AUTOSAR XML (schema 00044)
package /ComponentTypes
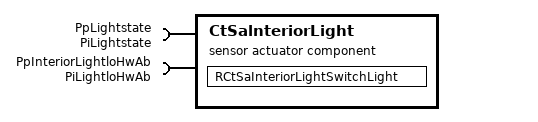
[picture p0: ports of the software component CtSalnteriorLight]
  sensor actuator sw component type CtSalnteriorLight
    require port PpLightstate: nonqueued-receiver-com-spec{data-element=DeLightstate, init-value=constant-reference=Clightoff}, required-interface=PiLightstate
    require port PpInteriorLightloHwAb: client-com-spec=WriteChannel, required-interface=PiLightloHwAb
    behavior CtSalnteriorLight_InternalBehavior: data-type-mapping=DemoTypeMapping, supports-multiple-instantiation=true
      data received event DRT_RCtSaInteriorLightSwitchLight_PpLightstate_DeLightstate: start-on-event=RCtSaInteriorLightSwitchLight, data=PpLightstate.DeLightstate
      runnable RCtSaInteriorLightSwitchLight
        data-receive-point-by-arguments:
          access REC_PpLightstate_DeLightstate: accessed-variable=PpLightstate.DeLightstate
        sync call SC_PpInteriorLightloHwAb_WriteChannel: operation=PpInteriorLightloHwAb.WriteChannel
  swc implementation CtSalnteriorLight_Implementation: behavior=CtSalnteriorLight_InternalBehavior
